VERSION ""

NS_ :

BS_:

BU_: XXX

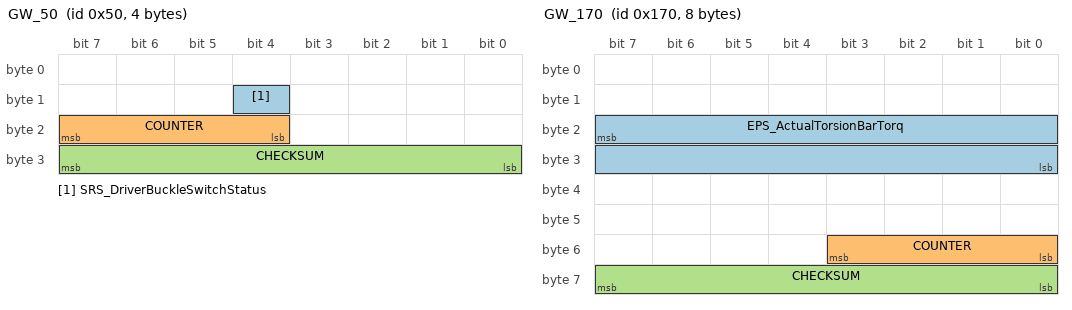
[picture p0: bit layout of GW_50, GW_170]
BO_ 80 GW_50: 4 XXX
 SG_ SRS_DriverBuckleSwitchStatus : 12|1@0+ (1,0) [0|1] "" XXX
 SG_ COUNTER : 23|4@0+ (1,0) [0|15] "" XXX
 SG_ CHECKSUM : 31|8@0+ (1,0) [0|255] "" XXX

BO_ 368 GW_170: 8 ESP
 SG_ EPS_ActualTorsionBarTorq : 23|16@0+ (1,-5533) [0|65535] "" XXX
 SG_ COUNTER : 51|4@0+ (1,0) [0|15] "" XXX
 SG_ CHECKSUM : 63|8@0+ (1,0) [0|255] "" XXX

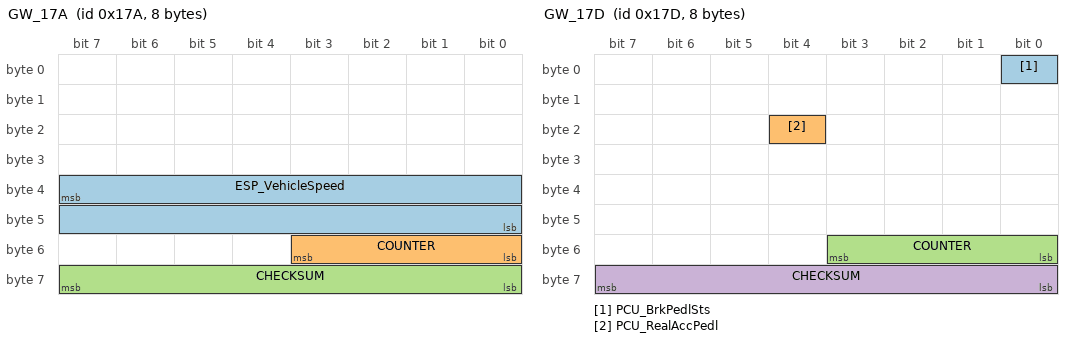
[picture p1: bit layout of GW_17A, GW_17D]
BO_ 378 GW_17A: 8 XXX
 SG_ ESP_VehicleSpeed : 39|16@0+ (0.05,0) [0|65535] "km/h" XXX
 SG_ COUNTER : 51|4@0+ (1,0) [0|15] "" XXX
 SG_ CHECKSUM : 63|8@0+ (1,0) [0|255] "" XXX

BO_ 381 GW_17D: 8 XXX
 SG_ PCU_BrkPedlSts : 0|1@0+ (1,0) [0|1] "" XXX
 SG_ PCU_RealAccPedl : 20|1@0+ (1,0) [0|1] "" XXX
 SG_ COUNTER : 51|4@0+ (1,0) [0|15] "" XXX
 SG_ CHECKSUM : 63|8@0+ (1,0) [0|255] "" XXX

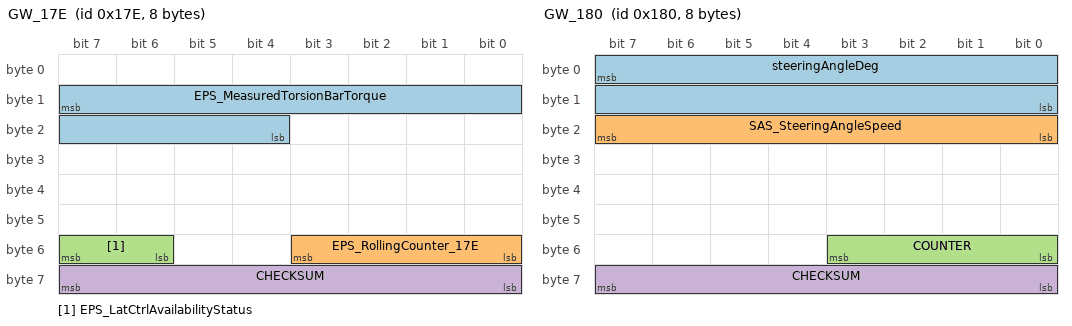
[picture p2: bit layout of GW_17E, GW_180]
BO_ 382 GW_17E: 8 XXX
 SG_ EPS_MeasuredTorsionBarTorque : 15|12@0- (0.001,0) [-2.048|2.047] "" XXX
 SG_ EPS_RollingCounter_17E : 51|4@0+ (1,0) [0|15] "" XXX
 SG_ EPS_LatCtrlAvailabilityStatus : 55|2@0+ (1,0) [0|3] "" XXX
 SG_ CHECKSUM : 63|8@0+ (1,0) [0|255] "" XXX

BO_ 384 GW_180: 8 XXX
 SG_ steeringAngleDeg : 7|16@0- (0.1,0) [-476|476] "deg" XXX
 SG_ SAS_SteeringAngleSpeed : 23|8@0+ (1,0) [0|255] "" XXX
 SG_ COUNTER : 51|4@0+ (1,0) [0|15] "" XXX
 SG_ CHECKSUM : 63|8@0+ (1,0) [0|255] "" XXX

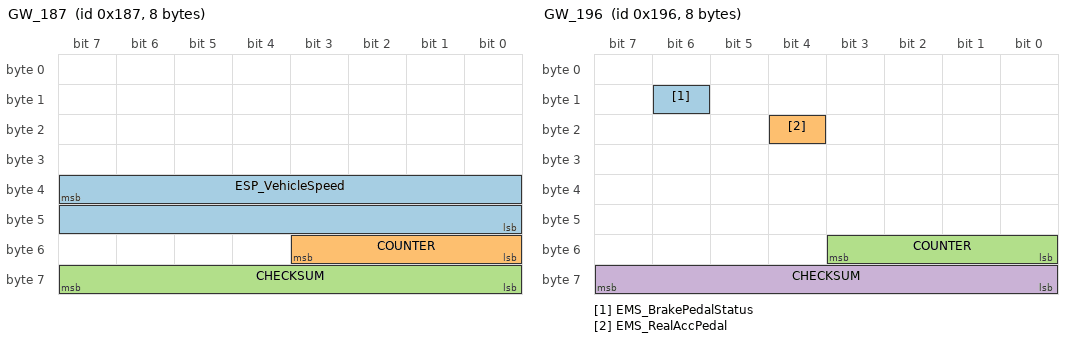
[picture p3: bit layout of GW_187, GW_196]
BO_ 391 GW_187: 8 XXX
 SG_ ESP_VehicleSpeed : 39|16@0+ (0.05,0) [0|65535] "km/h" XXX
 SG_ COUNTER : 51|4@0+ (1,0) [0|15] "" XXX
 SG_ CHECKSUM : 63|8@0+ (1,0) [0|255] "" XXX

BO_ 406 GW_196: 8 XXX
 SG_ EMS_BrakePedalStatus : 14|1@0+ (1,0) [0|1] "" XXX
 SG_ EMS_RealAccPedal : 20|1@0+ (1,0) [0|1] "" XXX
 SG_ COUNTER : 51|4@0+ (1,0) [0|15] "" XXX
 SG_ CHECKSUM : 63|8@0+ (1,0) [0|255] "" XXX

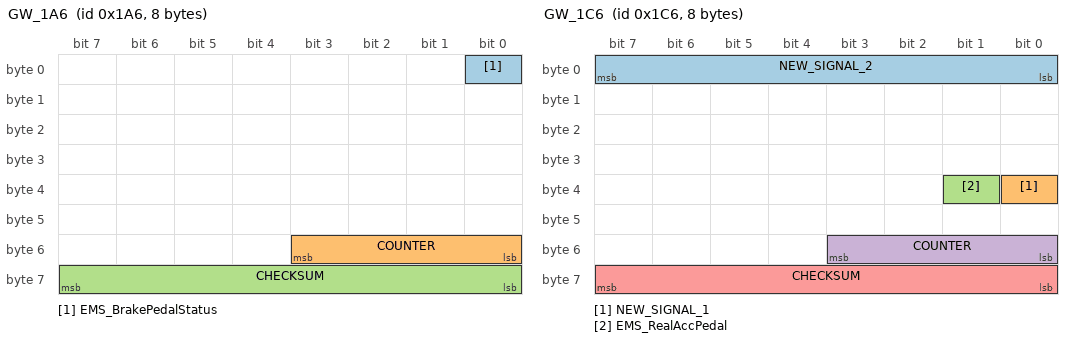
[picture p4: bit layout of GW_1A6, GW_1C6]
BO_ 422 GW_1A6: 8 XXX
 SG_ EMS_BrakePedalStatus : 0|1@0+ (1,0) [0|1] "" XXX
 SG_ COUNTER : 51|4@0+ (1,0) [0|15] "" XXX
 SG_ CHECKSUM : 63|8@0+ (1,0) [0|255] "" XXX

BO_ 442 GW_1BA: 32 XXX
 SG_ STEER_LIMIT_Up : 7|8@0- (0.1,0) [-12.8|12.7] "" XXX
 SG_ STEER_LIMIT_Down : 15|8@0- (0.1,0) [-12.8|12.7] "" XXX
 SG_ ACC_SteeringAngleReq_1BA : 16|1@0+ (1,0) [0|1] "" XXX
 SG_ ACC_SteeringAngleSub_1BA : 31|15@0- (0.1,0) [-1638|1638] "deg" XXX
 SG_ Counter_1BA : 51|4@0+ (1,0) [0|15] "" XXX
 SG_ CHECKSUM : 63|8@0+ (1,0) [0|255] "" XXX

BO_ 454 GW_1C6: 8 XXX
 SG_ NEW_SIGNAL_2 : 7|8@0+ (1,0) [0|255] "" XXX
 SG_ NEW_SIGNAL_1 : 32|1@0+ (1,0) [0|1] "" XXX
 SG_ EMS_RealAccPedal : 33|1@0+ (1,0) [0|1] "" XXX
 SG_ COUNTER : 51|4@0+ (1,0) [0|15] "" XXX
 SG_ CHECKSUM : 63|8@0+ (1,0) [0|255] "" XXX

BO_ 580 GW_244: 32 XXX
 SG_ ACC_Acceleration_24E : 7|16@0- (0.05,0) [-10|10] "m/s2" XXX
 SG_ ACC_ControlActive : 32|1@0+ (1,0) [0|1] "" XXX
 SG_ ACC_BrakeActive : 36|1@0+ (1,0) [0|1] "" XXX
 SG_ ACC_ACCMode : 41|3@0+ (1,0) [0|7] "" XXX
 SG_ ACC_RollingCounter_24E : 51|4@0+ (1,0) [0|15] "" XXX
 SG_ CHECKSUM : 63|8@0+ (1,0) [0|255] "" XXX
 SG_ ACC_AEBCtrlType : 86|3@0+ (1,0) [0|7] "" XXX
 SG_ ACC_FCWPreWarning : 87|1@0+ (1,0) [0|1] "" XXX
 SG_ ACC_ACCReq : 93|1@0+ (1,0) [0|1] "" XXX
 SG_ ACC_LongControlActive : 94|1@0+ (1,0) [0|1] "" XXX
 SG_ ACC_ACCEnable : 95|1@0+ (1,0) [0|1] "" XXX
 SG_ ACC_TorqueReq : 103|16@0- (1,-5000) [-10000|10000] "" XXX
 SG_ COUNTER_1 : 115|4@0+ (1,0) [0|15] "" XXX
 SG_ CHECKSUM_1 : 127|8@0+ (1,0) [0|255] "" XXX

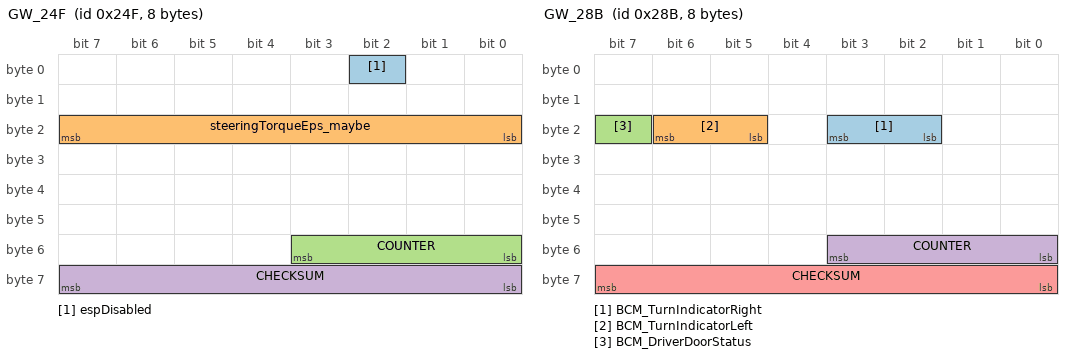
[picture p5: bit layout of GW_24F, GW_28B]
BO_ 591 GW_24F: 8 XXX
 SG_ espDisabled : 2|1@0+ (1,0) [0|1] "" XXX
 SG_ steeringTorqueEps_maybe : 23|8@0- (0.1,0) [0|255] "" XXX
 SG_ COUNTER : 51|4@0+ (1,0) [0|15] "" XXX
 SG_ CHECKSUM : 63|8@0+ (1,0) [0|255] "" XXX

BO_ 651 GW_28B: 8 XXX
 SG_ BCM_TurnIndicatorRight : 19|2@0+ (1,0) [0|3] "" XXX
 SG_ BCM_TurnIndicatorLeft : 22|2@0+ (1,0) [0|3] "" XXX
 SG_ BCM_DriverDoorStatus : 23|1@0+ (1,0) [0|1] "" XXX
 SG_ COUNTER : 51|4@0+ (1,0) [0|15] "" XXX
 SG_ CHECKSUM : 63|8@0+ (1,0) [0|255] "" XXX

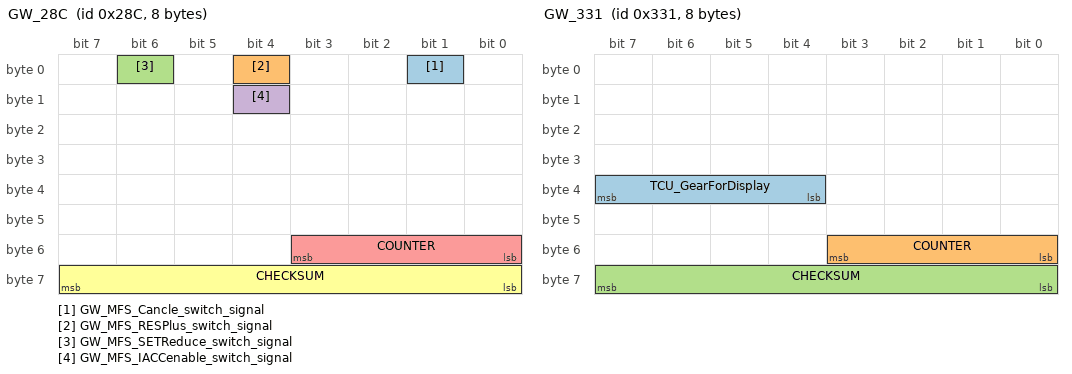
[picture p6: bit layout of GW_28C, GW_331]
BO_ 652 GW_28C: 8 XXX
 SG_ GW_MFS_Cancle_switch_signal : 1|1@0+ (1,0) [0|1] "" XXX
 SG_ GW_MFS_RESPlus_switch_signal : 4|1@0+ (1,0) [0|1] "" XXX
 SG_ GW_MFS_SETReduce_switch_signal : 6|1@0+ (1,0) [0|1] "" XXX
 SG_ GW_MFS_IACCenable_switch_signal : 12|1@0+ (1,0) [0|1] "" XXX
 SG_ COUNTER : 51|4@0+ (1,0) [0|15] "" XXX
 SG_ CHECKSUM : 63|8@0+ (1,0) [0|255] "" XXX

BO_ 676 GW_2A4: 64 XXX
 SG_ LCDAR_Left_BSD_LCAAlert : 7|2@0+ (1,0) [0|3] "" XXX
 SG_ LCDAR_BSD_LCAAlert : 9|2@0+ (1,0) [0|3] "" XXX
 SG_ COUNTER : 51|4@0+ (1,0) [0|15] "" XXX
 SG_ CHECKSUM : 63|8@0+ (1,0) [0|255] "" XXX

BO_ 775 GW_307: 64 XXX
 SG_ vCruise : 7|16@0+ (0.0078125,0) [0|250] "km/h" XXX
 SG_ sig_337 : 16|1@0+ (1,0) [0|1] "" XXX
 SG_ ACC_DistanceLevel : 18|2@0+ (1,0) [0|3] "" XXX
 SG_ sig_340 : 20|1@0+ (1,0) [0|1] "" XXX
 SG_ sig_341 : 21|1@0+ (1,0) [0|1] "" XXX
 SG_ Counter_35E : 51|4@0+ (1,0) [0|15] "" XXX
 SG_ CHECKSUM_1 : 63|8@0+ (1,0) [0|255] "" XXX
 SG_ COUNTER_2 : 115|4@0+ (1,0) [0|15] "" XXX
 SG_ CHECKSUM_2 : 127|8@0+ (1,0) [0|255] "" XXX
 SG_ COUNTER_3 : 179|4@0+ (1,0) [0|15] "" XXX
 SG_ CHECKSUM_3 : 191|8@0+ (1,0) [0|255] "" XXX
 SG_ COUNTER_4 : 243|4@0+ (1,0) [0|15] "" XXX
 SG_ CHECKSUM_4 : 255|8@0+ (1,0) [0|255] "" XXX

BO_ 794 GW_31A: 64 XXX
 SG_ Counter_36D : 51|4@0+ (1,0) [0|15] "" XXX
 SG_ CHECKSUM_1 : 63|8@0+ (1,0) [0|255] "" XXX
 SG_ ACC_IACCHWASignal : 72|1@0+ (1,0) [0|1] "" XXX
 SG_ COUNTER_2 : 115|4@0+ (1,0) [0|15] "" XXX
 SG_ CHECKSUM_2 : 127|8@0+ (1,0) [0|255] "" XXX
 SG_ ACC_IACCHWAMode : 135|3@0+ (1,0) [0|7] "" XXX
 SG_ ACC_IACCHWAState1 : 139|1@0+ (1,0) [0|1] "" XXX
 SG_ ACC_IACCHWAState2 : 141|2@0+ (1,0) [0|3] "" XXX
 SG_ COUNTER_3 : 179|4@0+ (1,0) [0|15] "" XXX
 SG_ CHECKSUM_3 : 191|8@0+ (1,0) [0|255] "" XXX
 SG_ COUNTER_4 : 243|4@0+ (1,0) [0|15] "" XXX
 SG_ CHECKSUM_4 : 255|8@0+ (1,0) [0|255] "" XXX
 SG_ ACC_IACCHWAEnable : 390|1@0+ (1,0) [0|1] "" XXX
 SG_ cruiseState : 391|1@0+ (1,0) [0|1] "" XXX
 SG_ steeringPressed : 398|1@0+ (1,0) [0|1] "" XXX

BO_ 817 GW_331: 8 XXX
 SG_ TCU_GearForDisplay : 39|4@0+ (1,-7) [0|15] "" XXX
 SG_ COUNTER : 51|4@0+ (1,0) [0|15] "" XXX
 SG_ CHECKSUM : 63|8@0+ (1,0) [0|255] "" XXX

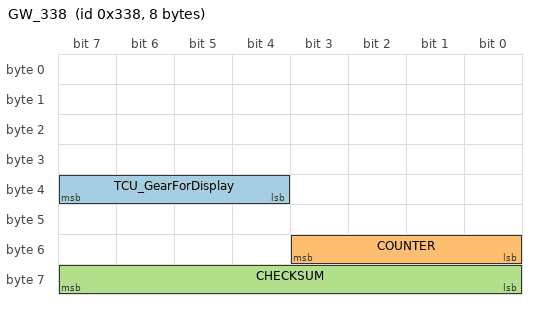
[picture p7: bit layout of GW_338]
BO_ 824 GW_338: 8 XXX
 SG_ TCU_GearForDisplay : 39|4@0+ (1,-7) [0|15] "" XXX
 SG_ COUNTER : 51|4@0+ (1,0) [0|15] "" XXX
 SG_ CHECKSUM : 63|8@0+ (1,0) [0|255] "" XXX

VAL_ 378 ESP_VehicleSpeed 65535 "Invalid";
VAL_ 391 ESP_VehicleSpeed 65535 "Invalid";
VAL_ 817 TCU_GearForDisplay 2 "N" 1 "R" 3 "D" 0 "P";
VAL_ 824 TCU_GearForDisplay 2 "N" 1 "R" 3 "D" 0 "P";
